# AVR32SD28 device description
Architecture: AVR8X; Family: AVR
Registers are 8-bit, read-write, reset 0x0 unless marked. A register's access mark holds for its fields unless they carry their own. Offsets are from the block's base; [hi:lo] are bit positions; {n}, {i} and the like mark numbered series; 'fields as' and 'values as' point back to an identical list.

## ERRCTRL — Error Controller
Instances: ERRCTRL 0x0E40
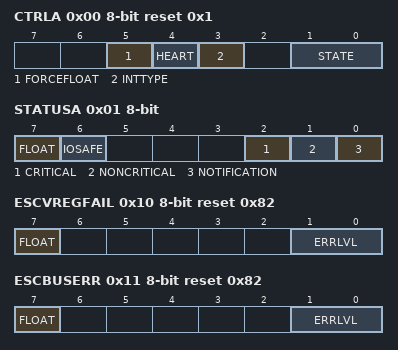
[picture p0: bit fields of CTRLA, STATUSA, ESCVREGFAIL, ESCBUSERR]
0x00 CTRLA reset 0x1 — Control A
  [5] FORCEFLOAT — Force I/O Float
  [4] HEART — Heartbeat Enable
  [3] INTTYPE — ALARM State Interrupt Type
    0=INT (Interrupt); 1=NMI (Non-maskable interrupt)
  [1:0] STATE — ERRCTRL State
    0=CONFIG (Configuration state); 1=NORMAL (Normal state); 2=ALARM (Alarm state); 3=FAULT (Fault state)
0x01 STATUSA ro reset not defined
  [7] FLOAT — Float I/O pins
    0=NORMAL (I/O pins are not forced to floating state); 1=FLOAT (I/O pins are forced to floating state)
  [6] IOSAFE — All I/O pins are in safe state
    0=NOSAFE (One or more I/O pins are not in safe state); 1=SAFE (All I/O pins are in a safe state)
  [2] CRITICAL — Critical Error Detected
    0=NOERROR (There are no Critical errors in the system); 1=ERROR (There are one or more Critical errors in the system)
  [1] NONCRITICAL — Noncritical Error Detected
    0=NOERROR (There are no Noncritical errors in the system); 1=ERROR (There are one or more Noncritical errors in the system)
  [0] NOTIFICATION — Notification Error Detected
    0=NOERROR (There are no Notification errors in the system); 1=ERROR (There are one or more Notification errors in the system)
0x02 TIMEOUT reset 0xFF — Timeout Value
0x03 TIMECNT ro reset 0xFF — Timeout Counter
  [7:0] TIMECNT — Timeout Counter Value
0x04 CAUSE ro reset not defined — Reset Cause
  [4:0] CAUSE
    0=VREGFAIL (VREG Low/High voltage detect); 1=BUSERR (Bus Error on data bus or parity error on data); 2=RAM2 (Data (RAM) ECC double bit or comparator error); 3=FLASH2 (Flash ECC double bit or comparator error); 4=OPC (Illegal opcode instruction or parity error on fetched instruction); 5=SPLIM (Stack Pointer Limit); 6=RAM1 (Data (RAM) ECC single bit error); 7=FLASH1 (Flash ECC single bit error); 8=VREGWARN (VREG diagnostic enter/exit or other SLPCTRL error); 9=CFD0; 10=CFD1; 11=CFM0 (CFM Frequency Error 0); 12=CFM1 (CFM Frequency Error 1); 13=SWDT (SWDT Error); 14=EEPROM (EEPROM ECC error); 15=EVSYS0 (Event system input 0); 16=EVSYS1 (Event system input 1)
0x10 ESCVREGFAIL reset 0x82 — Error Source Control VREGFAIL
  [7] FLOAT — Float all I/O pins
  [1:0] ERRLVL — Error Severity Level
    0=CRITICAL (Critical error); 2=NONCRITICAL (Noncritical error (reset value)); 3=NOTIFICATION (Notification error)
0x11 ESCBUSERR reset 0x82 — Error Source Control BUSERR
  fields as ESCVREGFAIL
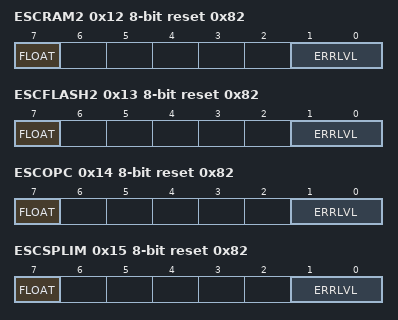
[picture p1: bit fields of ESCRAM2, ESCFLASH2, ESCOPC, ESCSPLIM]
0x12 ESCRAM2 reset 0x82 — Error Source Control RAM2
  fields as ESCVREGFAIL
0x13 ESCFLASH2 reset 0x82 — Error Source Control FLASH2
  fields as ESCVREGFAIL
0x14 ESCOPC reset 0x82 — Error Source Control OPC
  fields as ESCVREGFAIL
0x15 ESCSPLIM reset 0x82 — Error Source Control SPLIM
  fields as ESCVREGFAIL
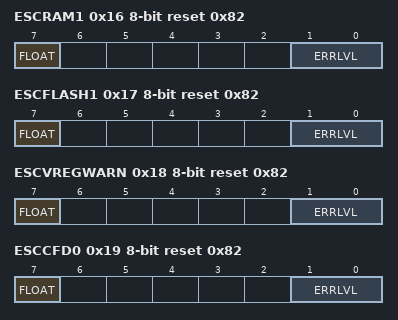
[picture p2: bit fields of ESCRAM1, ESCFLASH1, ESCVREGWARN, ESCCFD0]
0x16 ESCRAM1 reset 0x82 — Error Source Control RAM1
  fields as ESCVREGFAIL
0x17 ESCFLASH1 reset 0x82 — Error Source Control FLASH1
  fields as ESCVREGFAIL
0x18 ESCVREGWARN reset 0x82 — Error Source Control VREGWARN
  fields as ESCVREGFAIL
0x19 ESCCFD0 reset 0x82 — Error Source Control CFD0
  fields as ESCVREGFAIL
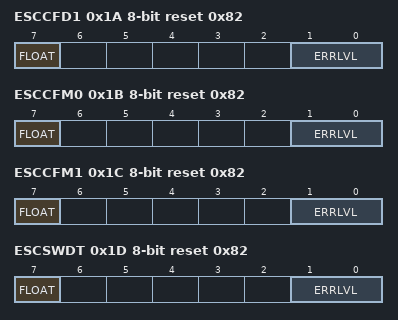
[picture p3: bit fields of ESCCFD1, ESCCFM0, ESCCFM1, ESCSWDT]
0x1A ESCCFD1 reset 0x82 — Error Source Control CFD1
  fields as ESCVREGFAIL
0x1B ESCCFM0 reset 0x82 — Error Source Control CFM0
  fields as ESCVREGFAIL
0x1C ESCCFM1 reset 0x82 — Error Source Control CFM1
  fields as ESCVREGFAIL
0x1D ESCSWDT reset 0x82 — Error Source Control SWDT
  fields as ESCVREGFAIL
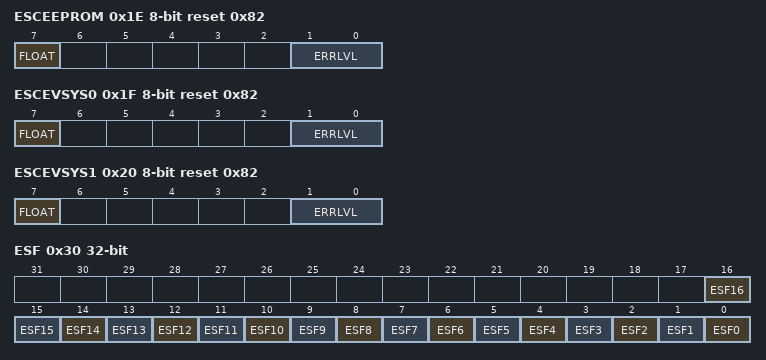
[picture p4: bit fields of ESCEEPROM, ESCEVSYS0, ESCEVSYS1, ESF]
0x1E ESCEEPROM reset 0x82 — Error Source Control EEPROM
  fields as ESCVREGFAIL
0x1F ESCEVSYS0 reset 0x82 — Error Source Control EVSYS0
  fields as ESCVREGFAIL
0x20 ESCEVSYS1 reset 0x82 — Error Source Control EVSYS1
  fields as ESCVREGFAIL
0x30 ESF 32-bit reset not defined — Error Status Flags
  [n] ESF{n} (n=0..16) — Error Status Flag {n}
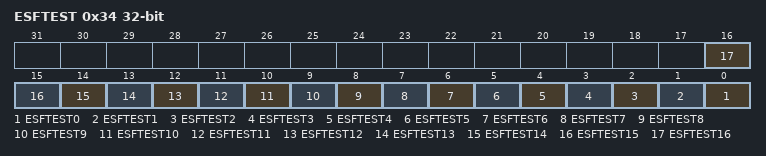
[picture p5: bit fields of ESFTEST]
0x34 ESFTEST 32-bit wo — Error Status Flag Test Injection
  [n] ESFTEST{n} (n=0..16) — Error Status Flag Test Injection {n}
